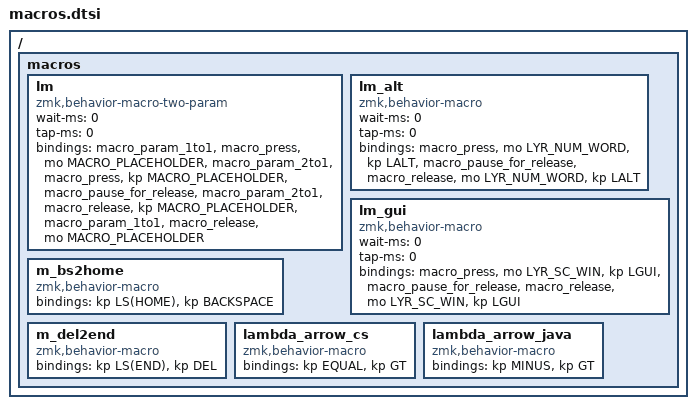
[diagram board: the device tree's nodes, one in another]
// Make sure settings.dtsi is included before this file

/ {
    macros {
        /**
         * Temporarily switches to a layer (`&mo`) while a modifier is held.
         * Analogous to QMK's `LM()`, using a parameterized macro.
         *
         * Params:
         *  1. Layer to switch to
         *  2. Modifier to press while layer is active
         *
         * Example:
         *  `&lm NUM_LAYER LSHIFT`
         */

        lm: lm {
            compatible = "zmk,behavior-macro-two-param";
            wait-ms = <0>;
            tap-ms = <0>;
            #binding-cells = <2>;
            bindings =
                <&macro_param_1to1>,
                <&macro_press>,
                <&mo MACRO_PLACEHOLDER &macro_param_2to1>,
                <&macro_press>,
                <&kp MACRO_PLACEHOLDER>,
                <&macro_pause_for_release>,
                <&macro_param_2to1>,
                <&macro_release>,
                <&kp MACRO_PLACEHOLDER &macro_param_1to1>,
                <&macro_release>,
                <&mo MACRO_PLACEHOLDER>;
        };

        lm_alt: lm_alt {
            compatible = "zmk,behavior-macro";
            wait-ms = <0>;
            tap-ms = <0>;
            #binding-cells = <0>;
            bindings =
                <&macro_press>,
                <&mo LYR_NUM_WORD &kp LALT>,
                <&macro_pause_for_release>,
                <&macro_release>,
                <&mo LYR_NUM_WORD &kp LALT>;
        };

        lm_gui: lm_gui {
            compatible = "zmk,behavior-macro";
            wait-ms = <0>;
            tap-ms = <0>;
            #binding-cells = <0>;
            bindings =
                <&macro_press>,
                <&mo LYR_SC_WIN &kp LGUI>,
                <&macro_pause_for_release>,
                <&macro_release>,
                <&mo LYR_SC_WIN &kp LGUI>;
        };

        m_bs2home: m_bs2home {
            compatible = "zmk,behavior-macro";
            #binding-cells = <0>;
            bindings = <&kp LS(HOME) &kp BACKSPACE>;
        };

        m_del2end: m_del2end {
            compatible = "zmk,behavior-macro";
            #binding-cells = <0>;
            bindings = <&kp LS(END) &kp DEL>;
        };

        lambda_arrow_cs: lambda_arrow_cs {
            compatible = "zmk,behavior-macro";
            #binding-cells = <0>;
            bindings = <&kp EQUAL &kp GT>;
        };

        lambda_arrow_java: lambda_arrow_java {
            compatible = "zmk,behavior-macro";
            #binding-cells = <0>;
            bindings = <&kp MINUS &kp GT>;
        };
    };
};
